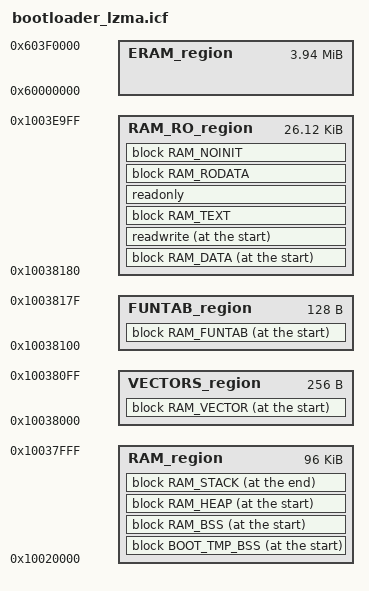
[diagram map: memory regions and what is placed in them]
/*###ICF### Section handled by ICF editor, don't touch! ****/
/*-Editor annotation file-*/
/* IcfEditorFile="$TOOLKIT_DIR$\config\ide\IcfEditor\cortex_v1_0.xml" */
/*-Specials-*/
//define symbol __ICFEDIT_intvec_start__ = 0x00000000;

/*-Memory Regions-*/
define symbol __ICFEDIT_region_RAM_start__         		= 0x10020000;
define symbol __ICFEDIT_region_RAM_end__           		= 0x10037FFF;

define symbol __ICFEDIT_region_VECTORS_start__         	= 0x10038000;
define symbol __ICFEDIT_region_VECTORS_end__           	= 0x100380FF;

define symbol __ICFEDIT_region_FUNTAB_start__         	= 0x10038100;
define symbol __ICFEDIT_region_FUNTAB_end__           	= 0x1003817F;

define symbol __ICFEDIT_region_RAM_RO_start__      		= 0x10038180;
define symbol __ICFEDIT_region_RAM_RO_end__        		= 0x1003E9FF;

define symbol __ICFEDIT_region_PSRAM_RAM_start__        = 0x60000000;
define symbol __ICFEDIT_region_PSRAM_RAM_end__          = 0x603F0000;    // 4MB

/*-Sizes-*/
/*define symbol __ICFEDIT_size_cstack__   = 0x400;*/
/*define symbol __ICFEDIT_size_heap__     = 0x800;*/
/**** End of ICF editor section. ###ICF###*/

define memory mem with size = 4G;

define region RAM_region					= mem:[from __ICFEDIT_region_RAM_start__   			to __ICFEDIT_region_RAM_end__];
define region RAM_RO_region					= mem:[from __ICFEDIT_region_RAM_RO_start__   		to __ICFEDIT_region_RAM_RO_end__];

define region FUNTAB_region					= mem:[from __ICFEDIT_region_FUNTAB_start__   		to __ICFEDIT_region_FUNTAB_end__];
define region VECTORS_region				= mem:[from __ICFEDIT_region_VECTORS_start__   		to __ICFEDIT_region_VECTORS_end__];

define region ERAM_region   	            = mem:[from __ICFEDIT_region_PSRAM_RAM_start__   	to __ICFEDIT_region_PSRAM_RAM_end__];
define exported symbol EramStart = start(ERAM_region);
define exported symbol EramEnd = end(ERAM_region);

/*define block CSTACK    with alignment = 8, size = __ICFEDIT_size_cstack__   { };*/
/*define block HEAP      with alignment = 8, size = __ICFEDIT_size_heap__     { };*/

//initialize by copy { readwrite };
//initialize by copy with packing = none { section __DLIB_PERTHREAD }; // Required in a multi-threaded application

//do not initialize  { section * };
do not initialize { readwrite };

/****************************************
 * BD RAM Section config                *
 ****************************************/

keep { section .rom_temp.bss };
keep { section .sboot.bss};
define block ROM_TEMP_BSS
{
    section .rom_temp.bss 
};
define block SBOOT_BSS
{
    section .sboot.bss
};
define block BOOT_TMP_BSS with fixed order
{
    block ROM_TEMP_BSS,
    block SBOOT_BSS
};

//place at start of RAM_region
//{
//    block BOOT_TMP_BSS
//};

keep { section .ram_vector_table };
define block RAM_VECTOR with alignment = 256, fixed order
{
    section .ram_vector_table
};
place at start of VECTORS_region 
{
    block RAM_VECTOR
};

keep { section .start.ram.data* };
define block RAM_FUNTAB with alignment = 32, fixed order
{
    section .start.ram.data*
};
place at start of FUNTAB_region
{
    block RAM_FUNTAB
};

define block RAM_BSS with fixed order
{
    section .bss*,
    section COMMON,
    zeroinit
};

define block SHT$$PREINIT_ARRAY { preinit_array };
define block SHT$$INIT_ARRAY { init_array };
define block CPP_INIT with alignment = 8, fixed order 
{        
    block SHT$$PREINIT_ARRAY,
    block SHT$$INIT_ARRAY 
};

define block RAM_DATA with fixed order
{
    section vtable, 
    section .data*,
    block CPP_INIT
};

keep { section .start.ram.sign* };
define block RAM_TEXT with alignment = 32, fixed order
{
    section .start.ram.sign*,
    section .text*
};

define block RAM_RODATA with fixed order
{
    section .rodata*,
    section .rodata.str1*
};

define block RAM_NOINIT with alignment = 32, fixed order
{
    section .sys_restore.bss*,
    section .ram.bss.noinit*,
    section .noinit
};

place at start of RAM_RO_region 
{
    block RAM_DATA,
    readwrite
};

place in RAM_RO_region 
{
    block RAM_TEXT,
    readonly,
    block RAM_RODATA
};

place in RAM_RO_region 
{
    block RAM_NOINIT
};

define block RAM_HEAP with fixed order
{
    section .heap*
};

place at start of RAM_region 
{
    block BOOT_TMP_BSS,
    block RAM_BSS,
    block RAM_HEAP
};										

define block RAM_STACK with fixed order
{
    section .stack*
};
place at end of RAM_region
{
    block RAM_STACK
};

include "..\..\..\component\soc\realtek\8710c\misc\bsp\ROM\romsym_iar_is.so";
define exported symbol Reset_Handler = 0x1001;
